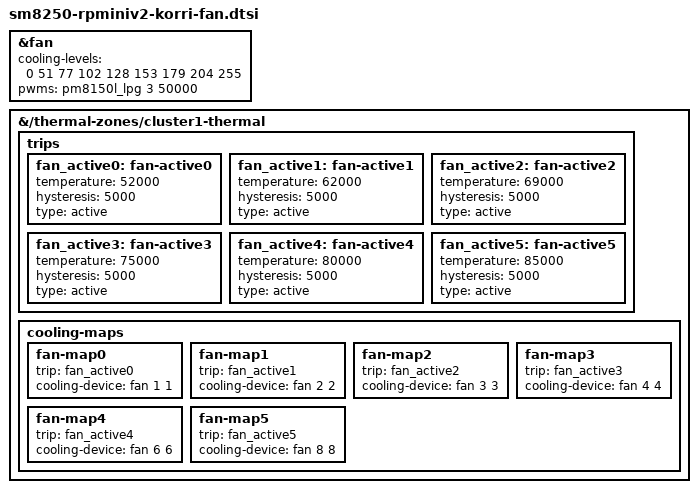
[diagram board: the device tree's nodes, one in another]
// SPDX-License-Identifier: BSD-3-Clause
/* Product-only quiet fan trips, runtime-proven on the Mini V2 with schedutil.
 * Keep the hardware-proven recovery DTB unchanged. Cooling levels and hysteresis
 * remain from ROCKNIX SM8250 PR #3339. No tach GPIO or userspace writes.
 */

&fan {
	cooling-levels = <0 51 77 102 128 153 179 204 255>;
	pwms = <&pm8150l_lpg 3 50000>;
};

&{/thermal-zones/cluster1-thermal} {
	trips {
		fan_active0: fan-active0 {
			temperature = <52000>;
			hysteresis = <5000>;
			type = "active";
		};

		fan_active1: fan-active1 {
			temperature = <62000>;
			hysteresis = <5000>;
			type = "active";
		};

		fan_active2: fan-active2 {
			temperature = <69000>;
			hysteresis = <5000>;
			type = "active";
		};

		fan_active3: fan-active3 {
			temperature = <75000>;
			hysteresis = <5000>;
			type = "active";
		};

		fan_active4: fan-active4 {
			temperature = <80000>;
			hysteresis = <5000>;
			type = "active";
		};

		fan_active5: fan-active5 {
			temperature = <85000>;
			hysteresis = <5000>;
			type = "active";
		};
	};

	cooling-maps {
		fan-map0 {
			trip = <&fan_active0>;
			cooling-device = <&fan 1 1>;
		};

		fan-map1 {
			trip = <&fan_active1>;
			cooling-device = <&fan 2 2>;
		};

		fan-map2 {
			trip = <&fan_active2>;
			cooling-device = <&fan 3 3>;
		};

		fan-map3 {
			trip = <&fan_active3>;
			cooling-device = <&fan 4 4>;
		};

		fan-map4 {
			trip = <&fan_active4>;
			cooling-device = <&fan 6 6>;
		};

		fan-map5 {
			trip = <&fan_active5>;
			cooling-device = <&fan 8 8>;
		};
	};
};
